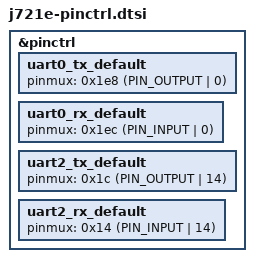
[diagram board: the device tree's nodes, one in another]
/* Copyright (C) 2023 BeagleBoard.org Foundation
 * Copyright (C) 2023 S Prashanth
 *
 * SPDX-License-Identifier: Apache-2.0
 */

#include <zephyr/dt-bindings/pinctrl/ti-k3-pinctrl.h>

&pinctrl {
	uart0_tx_default: uart0_tx_default {
		pinmux = <0x1e8 (PIN_OUTPUT | 0)>;
	};

	uart0_rx_default: uart0_rx_default {
		pinmux = <0x1ec (PIN_INPUT | 0)>;
	};

	uart2_tx_default: uart2_tx_default {
		pinmux = <0x1c (PIN_OUTPUT | 14)>;
	};

	uart2_rx_default: uart2_rx_default {
		pinmux = <0x14 (PIN_INPUT | 14)>;
	};
};
